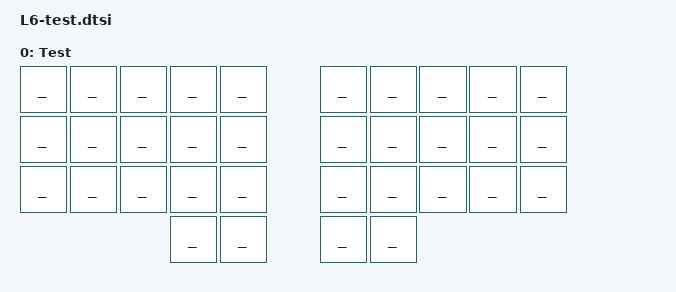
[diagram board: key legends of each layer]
/**
 *
 */

/ {
  keymap {
    compatible = "zmk,keymap";

	test_layer {
		label = "Test";
		bindings = <
//	╭───────────────┬───────────────┬───────────────┬───────────────┬───────────────╮   ╭───────────────┬───────────────┬───────────────┬───────────────┬───────────────╮
	________		________    	________		________		________			________        ________     	________        ________        ________
//	├───────────────┼───────────────┼───────────────┼───────────────┼───────────────┤   ├───────────────├───────────────┼───────────────┼───────────────┼───────────────┤
	________		________    	________		________		________			________        ________     	________        ________        ________
//	├───────────────┼───────────────┼───────────────┼───────────────┼───────────────┤   ├───────────────├───────────────┼───────────────┼───────────────┼───────────────┤
	________		________        ________        ________		________            ________        ________     	________        ________        ________
//	╰───────────────┴───────────────┼───────────────┼───────────────┼───────────────┤   ├───────────────├───────────────┼───────────────┼───────────────┴───────────────╯
	       											________        ________           	________		________
//                                                  ╰───────────────┴───────────────╯   ╰───────────────┴───────────────╯
			>;
		};
	};
};
